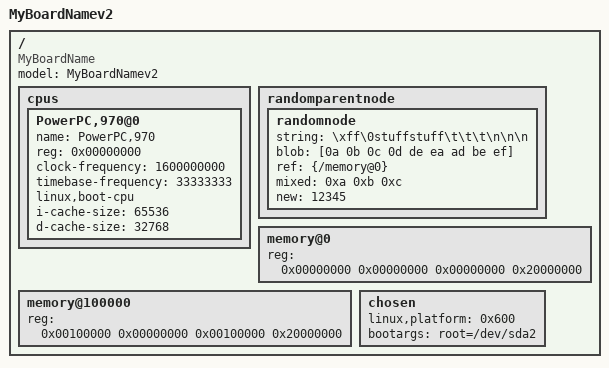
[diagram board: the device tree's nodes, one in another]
/dts-v1/;

/memreserve/ 0x1000000000000000 0x0000000002000000;
/memreserve/ 0x2000000000000000 0x0100000000000000;
/memreserve/ 0x0000000000000000 0x0000000000000014;

/ {
	model = "MyBoardNamev2";
	compatible = "MyBoardName", "MyBoardFamilyName", "MyBoardRevision";
	#address-cells = <2>;
	#size-cells = <2>;

	cpus {
		linux,phandle = <0x1>;
		#address-cells = <1>;
		#size-cells = <0>;
		PowerPC,970@0 {
			name = "PowerPC,970";
			device_type = "cpu";
			reg = <0x00000000>;
			clock-frequency = <1600000000>;
			timebase-frequency = <33333333>;
			linux,boot-cpu;
			i-cache-size = <65536>;
			d-cache-size = <32768>;
		};
	};

	randomparentnode {
		randomnode {
			string = "\xff\0stuffstuff\t\t\t\n\n\n";
			blob = [0a 0b 0c 0d de ea ad be ef];
			ref = < &{/memory@0} >;
			mixed = "abc",
				[1234],
				<0xa 0xb 0xc>;
			new = <12345>;
		};
	};

	memory@0 {
		device_type = "memory";
		memreg: reg = <
			0x00000000 0x00000000
			0x00000000 0x20000000>;
	};

	memory@100000 {
		device_type = "memory";
		memreg: reg = <
			0x00100000 0x00000000
			0x00100000 0x20000000>;
	};

	chosen {
		linux,platform = <0x600>;
		bootargs = "root=/dev/sda2";
	};

};
